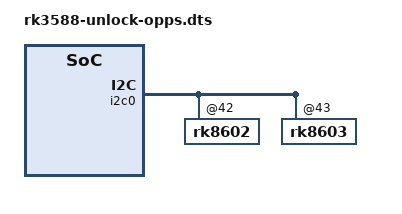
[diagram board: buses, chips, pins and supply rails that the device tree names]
/dts-v1/;
/plugin/;
/ {
	fragment@0 {
		target = <&cluster1_opp_table>;
		__overlay__ {
			opp-408000000 {
				opp-microvolt = <675000 675000 1350000>,
						<675000 675000 1350000>;
			};
			opp-600000000 {
				opp-microvolt = <675000 675000 1350000>,
						<675000 675000 1350000>;
			};
			opp-816000000 {
				opp-microvolt = <675000 675000 1350000>,
						<675000 675000 1350000>;
			};
			opp-1008000000 {
				opp-microvolt = <675000 675000 1350000>,
						<675000 675000 1350000>;
			};
			opp-1200000000 {
				opp-microvolt = <675000 675000 1350000>,
						<675000 675000 1350000>;
			};
			opp-1416000000 {
				opp-microvolt = <725000 725000 1350000>,
						<725000 725000 1350000>;
				opp-microvolt-L2 = <712500 712500 1350000>,
						   <712500 712500 1350000>;
				opp-microvolt-L3 = <700000 700000 1350000>,
						   <700000 700000 1350000>;
				opp-microvolt-L4 = <700000 700000 1350000>,
						   <700000 700000 1350000>;
				opp-microvolt-L5 = <687500 687500 1350000>,
						   <687500 687500 1350000>;
				opp-microvolt-L6 = <675000 675000 1350000>,
						   <675000 675000 1350000>;
				opp-microvolt-L7 = <675000 675000 1350000>,
						   <675000 675000 1350000>;
			};
			opp-1608000000 {
				opp-microvolt = <762500 762500 1350000>,
						<762500 762500 1350000>;
				opp-microvolt-L2 = <750000 750000 1350000>,
						   <750000 750000 1350000>;
				opp-microvolt-L3 = <737500 737500 1350000>,
						   <737500 737500 1350000>;
				opp-microvolt-L4 = <725000 725000 1350000>,
						   <725000 725000 1350000>;
				opp-microvolt-L5 = <712500 712500 1350000>,
						   <712500 712500 1350000>;
				opp-microvolt-L6 = <700000 700000 1350000>,
						   <700000 700000 1350000>;
				opp-microvolt-L7 = <700000 700000 1350000>,
						   <700000 700000 1350000>;
			};
			opp-1800000000 {
				opp-microvolt = <850000 850000 1350000>,
						<850000 850000 1350000>;
				opp-microvolt-L1 = <837500 837500 1350000>,
						   <837500 837500 1350000>;
				opp-microvolt-L2 = <825000 825000 1350000>,
						   <825000 825000 1350000>;
				opp-microvolt-L3 = <812500 812500 1350000>,
						   <812500 812500 1350000>;
				opp-microvolt-L4 = <800000 800000 1350000>,
						   <800000 800000 1350000>;
				opp-microvolt-L5 = <787500 787500 1350000>,
						   <787500 787500 1350000>;
				opp-microvolt-L6 = <775000 775000 1350000>,
						   <775000 775000 1350000>;
				opp-microvolt-L7 = <762500 762500 1350000>,
						   <762500 762500 1350000>;
			};
			opp-2016000000 {
				opp-microvolt = <925000 925000 1350000>,
						<925000 925000 1350000>;
				opp-microvolt-L1 = <912500 912500 1350000>,
						   <912500 912500 1350000>;
				opp-microvolt-L2 = <900000 900000 1350000>,
						   <900000 900000 1350000>;
				opp-microvolt-L3 = <887500 887500 1350000>,
						   <887500 887500 1350000>;
				opp-microvolt-L4 = <875000 875000 1350000>,
						   <875000 875000 1350000>;
				opp-microvolt-L5 = <862500 862500 1350000>,
						   <862500 862500 1350000>;
				opp-microvolt-L6 = <850000 850000 1350000>,
						   <850000 850000 1350000>;
				opp-microvolt-L7 = <837500 837500 1350000>,
						   <837500 837500 1350000>;
			};
			opp-2208000000 {
				opp-microvolt = <987500 987500 1350000>,
						<987500 987500 1350000>;
				opp-microvolt-L1 = <975000 975000 1350000>,
						   <975000 975000 1350000>;
				opp-microvolt-L2 = <962500 962500 1350000>,
						   <962500 962500 1350000>;
				opp-microvolt-L3 = <950000 950000 1350000>,
						   <950000 950000 1350000>;
				opp-microvolt-L4 = <962500 962500 1350000>,
						   <962500 962500 1350000>;
				opp-microvolt-L5 = <950000 950000 1350000>,
						   <950000 950000 1350000>;
				opp-microvolt-L6 = <925000 925000 1350000>,
						   <925000 925000 1350000>;
				opp-microvolt-L7 = <912500 912500 1350000>,
						   <912500 912500 1350000>;
			};
			opp-2256000000 {
				opp-microvolt = <1012500 1012500 1350000>,
						<1012500 1012500 1350000>;
				opp-supported-hw = <0xff 0xf0>;
			};
			opp-2304000000 {
				opp-microvolt = <1025000 1025000 1350000>,
						<1025000 1025000 1350000>;
				opp-supported-hw = <0xff 0xf0>;
			};
			opp-2352000000 {
				opp-microvolt = <1037500 1037500 1350000>,
						<1037500 1037500 1350000>;
				opp-supported-hw = <0xff 0xf0>;
			};
			opp-2400000000 {
				opp-microvolt = <1350000 1350000 1350000>,
						<1350000 1350000 1350000>;
				opp-supported-hw = <0xff 0xf0>;
			};
		};
	};
	fragment@1 {
		target = <&cluster2_opp_table>;
		__overlay__ {
			opp-408000000 {
				opp-microvolt = <675000 675000 1350000>,
						<675000 675000 1350000>;
			};
			opp-600000000 {
				opp-microvolt = <675000 675000 1350000>,
						<675000 675000 1350000>;
			};
			opp-816000000 {
				opp-microvolt = <675000 675000 1350000>,
						<675000 675000 1350000>;
			};
			opp-1008000000 {
				opp-microvolt = <675000 675000 1350000>,
						<675000 675000 1350000>;
			};
			opp-1200000000 {
				opp-microvolt = <675000 675000 1350000>,
						<675000 675000 1350000>;
			};
			opp-1416000000 {
				opp-microvolt = <725000 725000 1350000>,
						<725000 725000 1350000>;
				opp-microvolt-L2 = <712500 712500 1350000>,
						   <712500 712500 1350000>;
				opp-microvolt-L3 = <700000 700000 1350000>,
						   <700000 700000 1350000>;
				opp-microvolt-L4 = <700000 700000 1350000>,
						   <700000 700000 1350000>;
				opp-microvolt-L5 = <687500 687500 1350000>,
						   <687500 687500 1350000>;
				opp-microvolt-L6 = <675000 675000 1350000>,
						   <675000 675000 1350000>;
				opp-microvolt-L7 = <675000 675000 1350000>,
						   <675000 675000 1350000>;
			};
			opp-1608000000 {
				opp-microvolt = <762500 762500 1350000>,
						<762500 762500 1350000>;
				opp-microvolt-L2 = <750000 750000 1350000>,
						   <750000 750000 1350000>;
				opp-microvolt-L3 = <737500 737500 1350000>,
						   <737500 737500 1350000>;
				opp-microvolt-L4 = <725000 725000 1350000>,
						   <725000 725000 1350000>;
				opp-microvolt-L5 = <712500 712500 1350000>,
						   <712500 712500 1350000>;
				opp-microvolt-L6 = <700000 700000 1350000>,
						   <700000 700000 1350000>;
				opp-microvolt-L7 = <700000 700000 1350000>,
						   <700000 700000 1350000>;
			};
			opp-1800000000 {
				opp-microvolt = <850000 850000 1350000>,
						<850000 850000 1350000>;
				opp-microvolt-L1 = <837500 837500 1350000>,
						   <837500 837500 1350000>;
				opp-microvolt-L2 = <825000 825000 1350000>,
						   <825000 825000 1350000>;
				opp-microvolt-L3 = <812500 812500 1350000>,
						   <812500 812500 1350000>;
				opp-microvolt-L4 = <800000 800000 1350000>,
						   <800000 800000 1350000>;
				opp-microvolt-L5 = <787500 787500 1350000>,
						   <787500 787500 1350000>;
				opp-microvolt-L6 = <775000 775000 1350000>,
						   <775000 775000 1350000>;
				opp-microvolt-L7 = <762500 762500 1350000>,
						   <762500 762500 1350000>;
			};
			opp-2016000000 {
				opp-microvolt = <925000 925000 1350000>,
						<925000 925000 1350000>;
				opp-microvolt-L1 = <912500 912500 1350000>,
						   <912500 912500 1350000>;
				opp-microvolt-L2 = <900000 900000 1350000>,
						   <900000 900000 1350000>;
				opp-microvolt-L3 = <887500 887500 1350000>,
						   <887500 887500 1350000>;
				opp-microvolt-L4 = <875000 875000 1350000>,
						   <875000 875000 1350000>;
				opp-microvolt-L5 = <862500 862500 1350000>,
						   <862500 862500 1350000>;
				opp-microvolt-L6 = <850000 850000 1350000>,
						   <850000 850000 1350000>;
				opp-microvolt-L7 = <837500 837500 1350000>,
						   <837500 837500 1350000>;
			};
			opp-2208000000 {
				opp-microvolt = <987500 987500 1350000>,
						<987500 987500 1350000>;
				opp-microvolt-L1 = <975000 975000 1350000>,
						   <975000 975000 1350000>;
				opp-microvolt-L2 = <962500 962500 1350000>,
						   <962500 962500 1350000>;
				opp-microvolt-L3 = <950000 950000 1350000>,
						   <950000 950000 1350000>;
				opp-microvolt-L4 = <962500 962500 1350000>,
						   <962500 962500 1350000>;
				opp-microvolt-L5 = <950000 950000 1350000>,
						   <950000 950000 1350000>;
				opp-microvolt-L6 = <925000 925000 1350000>,
						   <925000 925000 1350000>;
				opp-microvolt-L7 = <912500 912500 1350000>,
						   <912500 912500 1350000>;
			};
			opp-2256000000 {
				opp-microvolt = <1012500 1012500 1350000>,
						<1012500 1012500 1350000>;
				opp-supported-hw = <0xff 0xf0>;
			};
			opp-2304000000 {
				opp-microvolt = <1025000 1025000 1350000>,
						<1025000 1025000 1350000>;
				opp-supported-hw = <0xff 0xf0>;
			};
			opp-2352000000 {
				opp-microvolt = <1037500 1037500 1350000>,
						<1037500 1037500 1350000>;
				opp-supported-hw = <0xff 0xf0>;
			};
			opp-2400000000 {
				opp-microvolt = <1350000 1350000 1350000>,
						<1350000 1350000 1350000>;
				opp-supported-hw = <0xff 0xf0>;
			};
		};
	};
	fragment@2 {
		target = <&dmc>;
		__overlay__ {
			upthreshold = <20>;
		};
	};
	fragment@3 {
		target = <&i2c0>;
		__overlay__ {
			rk8602@42 {
				regulator-max-microvolt = <0x16e360>;
			};
			rk8603@43 {
				regulator-max-microvolt = <0x16e360>;
			};
		};
	};
};
